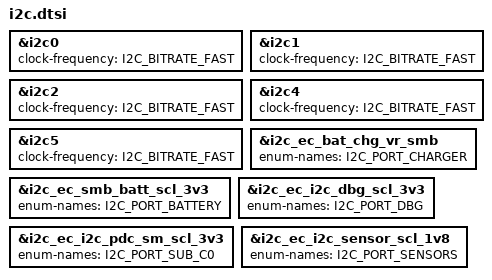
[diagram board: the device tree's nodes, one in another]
/* Copyright 2026 The ChromiumOS Authors
 * Use of this source code is governed by a BSD-style license that can be
 * found in the LICENSE file.
 */


&i2c0 {
	clock-frequency = <I2C_BITRATE_FAST>;
};

&i2c1 {
	clock-frequency = <I2C_BITRATE_FAST>;
};

&i2c2 {
	clock-frequency = <I2C_BITRATE_FAST>;
};

&i2c4 {
	clock-frequency = <I2C_BITRATE_FAST>;
};

&i2c5 {
	clock-frequency = <I2C_BITRATE_FAST>;
};

&i2c_ec_bat_chg_vr_smb {
	enum-names = "I2C_PORT_CHARGER";
};

&i2c_ec_smb_batt_scl_3v3 {
	enum-names = "I2C_PORT_BATTERY";
};

&i2c_ec_i2c_dbg_scl_3v3 {
	enum-names = "I2C_PORT_DBG";
};

&i2c_ec_i2c_pdc_sm_scl_3v3 {
	enum-names = "I2C_PORT_SUB_C0";
};

&i2c_ec_i2c_sensor_scl_1v8 {
	enum-names = "I2C_PORT_SENSORS";
};
